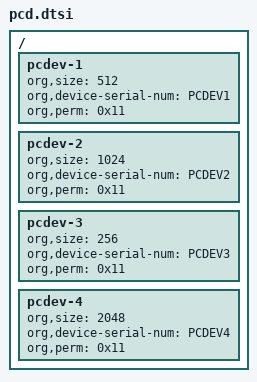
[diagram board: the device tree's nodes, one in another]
/ {
	pcdev-1 {
		org,size = <512>;
		org,device-serial-num = "PCDEV1";
		org,perm = <0x11>;
	};

	pcdev-2 {
		org,size = <1024>;
		org,device-serial-num = "PCDEV2";
		org,perm = <0x11>;
	};

	pcdev-3 {
		org,size = <256>;
		org,device-serial-num = "PCDEV3";
		org,perm = <0x11>;
	};

	pcdev-4 {
		org,size = <2048>;
		org,device-serial-num = "PCDEV4";
		org,perm = <0x11>;
	};
};
